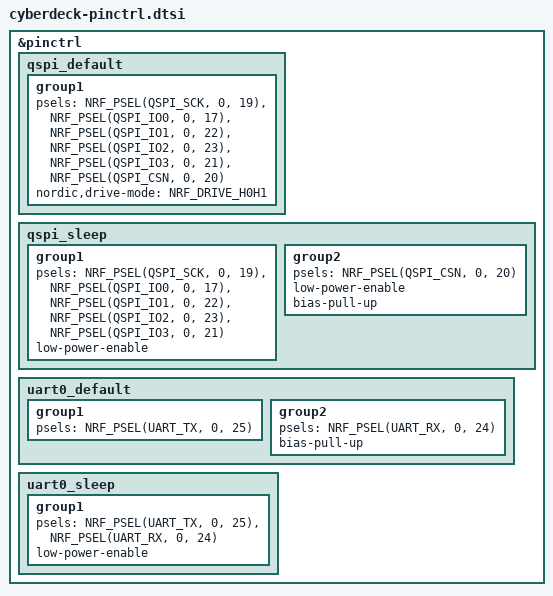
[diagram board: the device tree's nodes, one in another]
/*
 * Copyright (c) 2026 Core Devices LLC
 * SPDX-License-Identifier: Apache-2.0
 */

#include <zephyr/dt-bindings/pinctrl/nrf-pinctrl.h>

&pinctrl {
	qspi_default: qspi_default {
		group1 {
			psels = <NRF_PSEL(QSPI_SCK, 0, 19)>,
				<NRF_PSEL(QSPI_IO0, 0, 17)>,
				<NRF_PSEL(QSPI_IO1, 0, 22)>,
				<NRF_PSEL(QSPI_IO2, 0, 23)>,
				<NRF_PSEL(QSPI_IO3, 0, 21)>,
				<NRF_PSEL(QSPI_CSN, 0, 20)>;
			nordic,drive-mode = <NRF_DRIVE_H0H1>;
		};
	};

	qspi_sleep: qspi_sleep {
		group1 {
			psels = <NRF_PSEL(QSPI_SCK, 0, 19)>,
				<NRF_PSEL(QSPI_IO0, 0, 17)>,
				<NRF_PSEL(QSPI_IO1, 0, 22)>,
				<NRF_PSEL(QSPI_IO2, 0, 23)>,
				<NRF_PSEL(QSPI_IO3, 0, 21)>;
			low-power-enable;
		};

		group2 {
			psels = <NRF_PSEL(QSPI_CSN, 0, 20)>;
			low-power-enable;
			bias-pull-up;
		};
	};

	uart0_default: uart0_default {
		group1 {
			psels = <NRF_PSEL(UART_TX, 0, 25)>;
		};

		group2 {
			psels = <NRF_PSEL(UART_RX, 0, 24)>;
			bias-pull-up;
		};
	};

	uart0_sleep: uart0_sleep {
		group1 {
			psels = <NRF_PSEL(UART_TX, 0, 25)>,
				<NRF_PSEL(UART_RX, 0, 24)>;
			low-power-enable;
		};
	};
};
